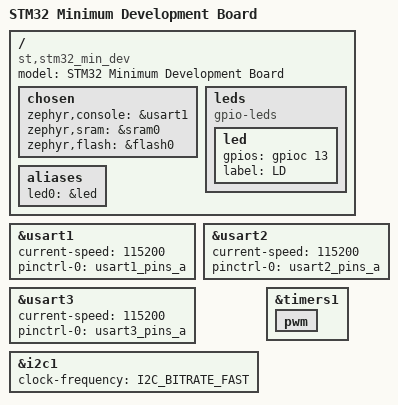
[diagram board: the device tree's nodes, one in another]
/*
 * Copyright (c) 2017, embedjournal.com
 *
 * SPDX-License-Identifier: Apache-2.0
 */

/dts-v1/;
#include <st/f1/stm32f103X8.dtsi>

/ {
	model = "STM32 Minimum Development Board";
	compatible = "st,stm32_min_dev", "st,stm32f103c8";

	chosen {
		zephyr,console = &usart1;
		zephyr,sram = &sram0;
		zephyr,flash = &flash0;
	};

	leds {
		compatible = "gpio-leds";
		led: led {
			gpios = <&gpioc 13 GPIO_INT_ACTIVE_HIGH>;
			label = "LD";
		};
	};

	aliases {
		led0 = &led;
	};
};

&usart1 {
	current-speed = <115200>;
	pinctrl-0 = <&usart1_pins_a>;
	pinctrl-names = "default";
	status = "ok";
};

&usart2 {
	current-speed = <115200>;
	pinctrl-0 = <&usart2_pins_a>;
	pinctrl-names = "default";
};

&usart3 {
	current-speed = <115200>;
	pinctrl-0 = <&usart3_pins_a>;
	pinctrl-names = "default";
};

&i2c1 {
	status = "ok";
	clock-frequency = <I2C_BITRATE_FAST>;
};

&timers1 {
	status = "ok";

	pwm {
		status = "ok";
	};
};
